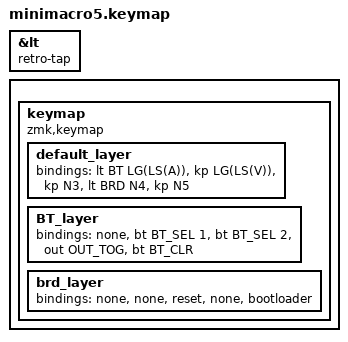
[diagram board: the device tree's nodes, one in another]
/*
 * Copyright (c) 2020 The ZMK Contributors
 *
 * SPDX-License-Identifier: MIT
 */

#include <behaviors.dtsi>
#include <dt-bindings/zmk/keys.h>
#include <dt-bindings/zmk/bt.h>
#include <dt-bindings/zmk/outputs.h>

#define DEFAULT 0
#define BT  1
#define BRD 2

&lt {
    retro-tap;
};

{
    keymap {
        compatible = "zmk,keymap";

        default_layer {
            bindings = <
                &lt BT LG(LS(A)) &kp LG(LS(V))   &kp N3  &lt BRD N4  &kp N5
            >;
        };

        BT_layer {
            bindings = <
                &none   &bt BT_SEL 1    &bt BT_SEL 2    &out OUT_TOG    &bt BT_CLR
            >;
        };

        brd_layer {
            bindings = <
                &none   &none   &reset   &none   &bootloader
            >;
        };

    };
};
